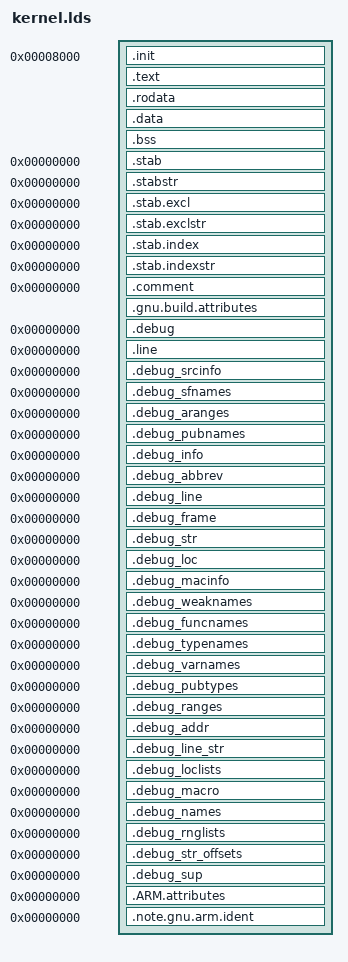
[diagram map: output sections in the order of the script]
define(`TEXT_PARTS', `.text.unlikely .text.*_unlikely .text.unlikely.*
		.text.hot .text.hot.* SORT(.text.sorted.*) .text .stub .text.*
		.gnu.linkonce.t.* .gnu.warning')

ENTRY(_start)
SECTIONS
{
	. = 0x00008000;
	.init : { *(.init) }
	.text : { *( TEXT_PARTS ) }
	.rodata : { *(.rodata .rodata.*) }
	. = ALIGN(1<<20);
	.data : { *(.data .data.*) }
	.bss  : { *(.bss .bss.*)  }

	/* We should not need thumb mode, hence we do not need glue code.
	   If you want to use thumb mode you will have to figure out how to either
	   use it only in the kernel or the userspace. Or figure out how to
	   configure the corresponding section once you enable the mmu */
	/DISCARD/ : { "linker stubs"(.glue_7 .glue_7t .vfp11_veneer .v4_bx) }

	/* We do not actually use the features but these sections are created
	 anyways, hence we discard these orphan explcitly. */
	/DISCARD/ : { *(.iplt* .rel* .igot*) }

	/* taken from the default linker script via --verbose */
	/* Stabs debugging sections.  */
	.stab          0 : { *(.stab) }
	.stabstr       0 : { *(.stabstr) }
	.stab.excl     0 : { *(.stab.excl) }
	.stab.exclstr  0 : { *(.stab.exclstr) }
	.stab.index    0 : { *(.stab.index) }
	.stab.indexstr 0 : { *(.stab.indexstr) }
	.comment 0 (INFO) : { *(.comment); LINKER_VERSION; }
	.gnu.build.attributes : { *(.gnu.build.attributes .gnu.build.attributes.*) }
	/* DWARF debug sections.
	   Symbols in the DWARF debugging sections are relative to the beginning
	   of the section so we begin them at 0.  */
	/* DWARF 1.  */
	.debug          0 : { *(.debug) }
	.line           0 : { *(.line) }
	/* GNU DWARF 1 extensions.  */
	.debug_srcinfo  0 : { *(.debug_srcinfo) }
	.debug_sfnames  0 : { *(.debug_sfnames) }
	/* DWARF 1.1 and DWARF 2.  */
	.debug_aranges  0 : { *(.debug_aranges) }
	.debug_pubnames 0 : { *(.debug_pubnames) }
	/* DWARF 2.  */
	.debug_info     0 : { *(.debug_info .gnu.linkonce.wi.*) }
	.debug_abbrev   0 : { *(.debug_abbrev) }
	.debug_line     0 : { *(.debug_line .debug_line.* .debug_line_end) }
	.debug_frame    0 : { *(.debug_frame) }
	.debug_str      0 : { *(.debug_str) }
	.debug_loc      0 : { *(.debug_loc) }
	.debug_macinfo  0 : { *(.debug_macinfo) }
	/* SGI/MIPS DWARF 2 extensions.  */
	.debug_weaknames 0 : { *(.debug_weaknames) }
	.debug_funcnames 0 : { *(.debug_funcnames) }
	.debug_typenames 0 : { *(.debug_typenames) }
	.debug_varnames  0 : { *(.debug_varnames) }
	/* DWARF 3.  */
	.debug_pubtypes 0 : { *(.debug_pubtypes) }
	.debug_ranges   0 : { *(.debug_ranges) }
	/* DWARF 5.  */
	.debug_addr     0 : { *(.debug_addr) }
	.debug_line_str 0 : { *(.debug_line_str) }
	.debug_loclists 0 : { *(.debug_loclists) }
	.debug_macro    0 : { *(.debug_macro) }
	.debug_names    0 : { *(.debug_names) }
	.debug_rnglists 0 : { *(.debug_rnglists) }
	.debug_str_offsets 0 : { *(.debug_str_offsets) }
	.debug_sup      0 : { *(.debug_sup) }
	.ARM.attributes 0 : { KEEP (*(.ARM.attributes)) KEEP (*(.gnu.attributes)) }
	.note.gnu.arm.ident 0 : { KEEP (*(.note.gnu.arm.ident)) }
	/DISCARD/ : { *(.note.GNU-stack) *(.gnu_debuglink) *(.gnu.lto_*) *(.gnu_object_only) }
}
